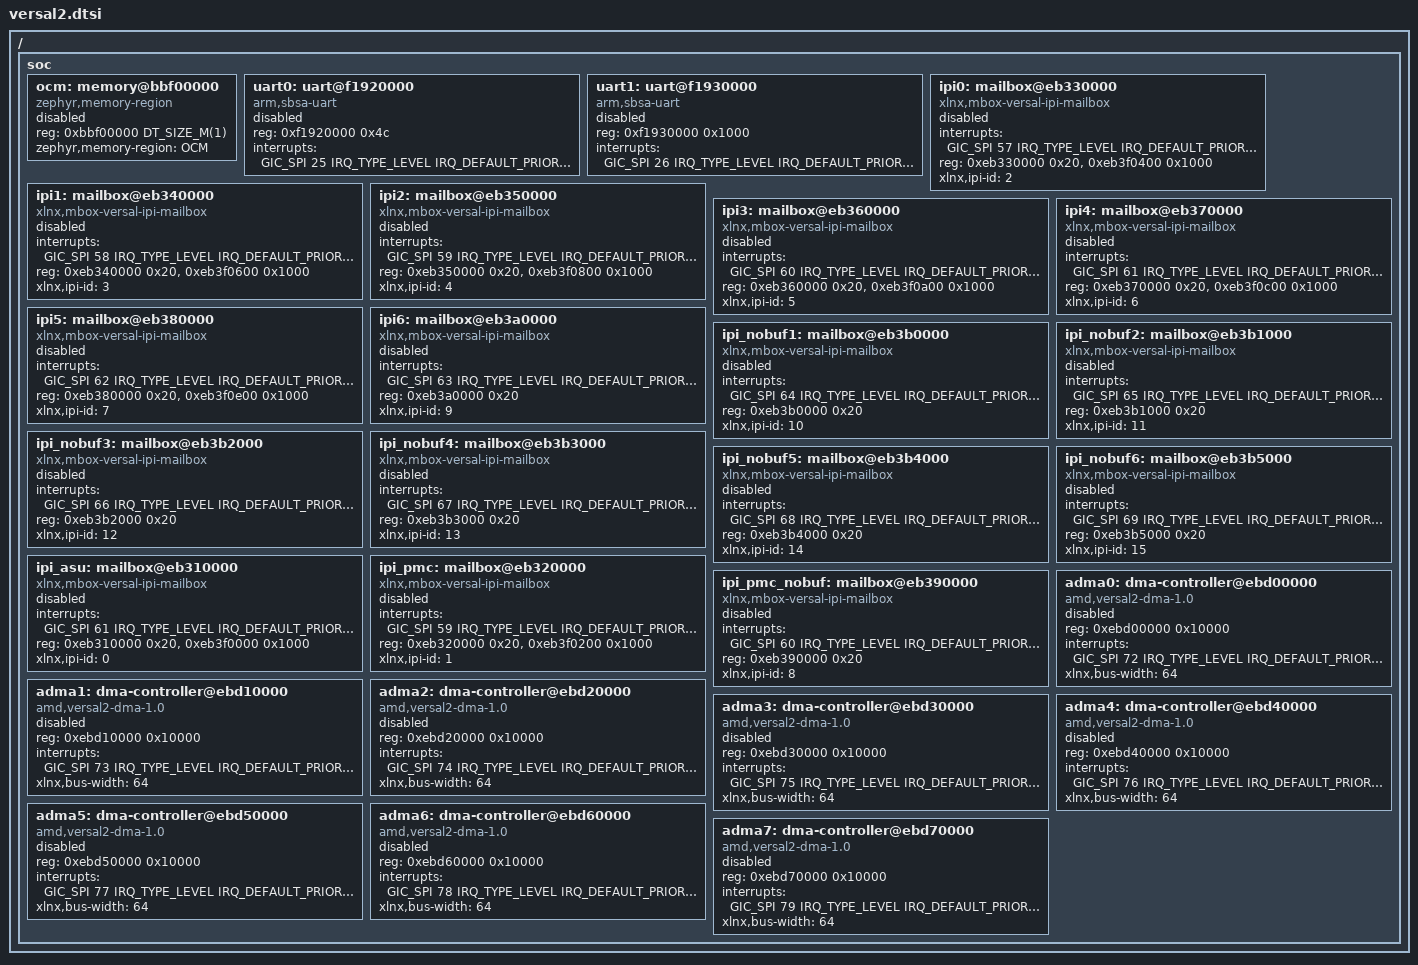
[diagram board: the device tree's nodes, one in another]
/*
 * Copyright (c) 2025, Advanced Micro Devices, Inc.
 *
 * SPDX-License-Identifier: Apache-2.0
 */

/ {
	soc: soc {
		ocm: memory@bbf00000 {
			compatible = "zephyr,memory-region";
			reg = <0xbbf00000 DT_SIZE_M(1)>;
			status = "disabled";
			zephyr,memory-region = "OCM";
		};

		uart0: uart@f1920000 {
			compatible = "arm,sbsa-uart";
			reg = <0xf1920000 0x4c>;
			status = "disabled";
			interrupt-names = "irq_0";
			interrupts = <GIC_SPI 25 IRQ_TYPE_LEVEL IRQ_DEFAULT_PRIORITY>;
		};

		uart1: uart@f1930000 {
			compatible = "arm,sbsa-uart";
			reg = <0xf1930000 0x1000>;
			status = "disabled";
			interrupt-names = "irq_1";
			interrupts = <GIC_SPI 26 IRQ_TYPE_LEVEL IRQ_DEFAULT_PRIORITY>;
		};

		ipi0: mailbox@eb330000 {
			compatible = "xlnx,mbox-versal-ipi-mailbox";
			status = "disabled";
			interrupts = <GIC_SPI 57 IRQ_TYPE_LEVEL IRQ_DEFAULT_PRIORITY>;
			reg = <0xeb330000 0x20>, <0xeb3f0400 0x1000>;
			reg-names = "ctrl", "msg";
			xlnx,ipi-id = <2>;
			#address-cells = <1>;
			#size-cells = <1>;
		};

		ipi1: mailbox@eb340000 {
			compatible = "xlnx,mbox-versal-ipi-mailbox";
			status = "disabled";
			interrupts = <GIC_SPI 58 IRQ_TYPE_LEVEL IRQ_DEFAULT_PRIORITY>;
			reg = <0xeb340000 0x20>, <0xeb3f0600 0x1000>;
			reg-names = "ctrl", "msg";
			xlnx,ipi-id = <3>;
			#address-cells = <1>;
			#size-cells = <1>;
		};

		ipi2: mailbox@eb350000 {
			compatible = "xlnx,mbox-versal-ipi-mailbox";
			status = "disabled";
			interrupts = <GIC_SPI 59 IRQ_TYPE_LEVEL IRQ_DEFAULT_PRIORITY>;
			reg = <0xeb350000 0x20>, <0xeb3f0800 0x1000>;
			reg-names = "ctrl", "msg";
			xlnx,ipi-id = <4>;
			#address-cells = <1>;
			#size-cells = <1>;
		};

		ipi3: mailbox@eb360000 {
			compatible = "xlnx,mbox-versal-ipi-mailbox";
			status = "disabled";
			interrupts = <GIC_SPI 60 IRQ_TYPE_LEVEL IRQ_DEFAULT_PRIORITY>;
			reg = <0xeb360000 0x20>, <0xeb3f0a00 0x1000>;
			reg-names = "ctrl", "msg";
			xlnx,ipi-id = <5>;
			#address-cells = <1>;
			#size-cells = <1>;
		};

		ipi4: mailbox@eb370000 {
			compatible = "xlnx,mbox-versal-ipi-mailbox";
			status = "disabled";
			interrupts = <GIC_SPI 61 IRQ_TYPE_LEVEL IRQ_DEFAULT_PRIORITY>;
			reg = <0xeb370000 0x20>, <0xeb3f0c00 0x1000>;
			reg-names = "ctrl", "msg";
			xlnx,ipi-id = <6>;
			#address-cells = <1>;
			#size-cells = <1>;
		};

		ipi5: mailbox@eb380000 {
			compatible = "xlnx,mbox-versal-ipi-mailbox";
			status = "disabled";
			interrupts = <GIC_SPI 62 IRQ_TYPE_LEVEL IRQ_DEFAULT_PRIORITY>;
			reg = <0xeb380000 0x20>, <0xeb3f0e00 0x1000>;
			reg-names = "ctrl", "msg";
			xlnx,ipi-id = <7>;
			#address-cells = <1>;
			#size-cells = <1>;
		};

		ipi6: mailbox@eb3a0000 {
			compatible = "xlnx,mbox-versal-ipi-mailbox";
			status = "disabled";
			interrupts = <GIC_SPI 63 IRQ_TYPE_LEVEL IRQ_DEFAULT_PRIORITY>;
			reg = <0xeb3a0000 0x20>;
			reg-names = "ctrl";
			xlnx,ipi-id = <9>;
			#address-cells = <1>;
			#size-cells = <1>;
		};

		ipi_nobuf1: mailbox@eb3b0000 {
			compatible = "xlnx,mbox-versal-ipi-mailbox";
			status = "disabled";
			interrupts = <GIC_SPI 64 IRQ_TYPE_LEVEL IRQ_DEFAULT_PRIORITY>;
			reg = <0xeb3b0000 0x20>;
			reg-names = "ctrl";
			xlnx,ipi-id = <10>;
			#address-cells = <1>;
			#size-cells = <1>;
		};

		ipi_nobuf2: mailbox@eb3b1000 {
			compatible = "xlnx,mbox-versal-ipi-mailbox";
			status = "disabled";
			interrupts = <GIC_SPI 65 IRQ_TYPE_LEVEL IRQ_DEFAULT_PRIORITY>;
			reg = <0xeb3b1000 0x20>;
			reg-names = "ctrl";
			xlnx,ipi-id = <11>;
			#address-cells = <1>;
			#size-cells = <1>;
		};

		ipi_nobuf3: mailbox@eb3b2000 {
			compatible = "xlnx,mbox-versal-ipi-mailbox";
			status = "disabled";
			interrupts = <GIC_SPI 66 IRQ_TYPE_LEVEL IRQ_DEFAULT_PRIORITY>;
			reg = <0xeb3b2000 0x20>;
			reg-names = "ctrl";
			xlnx,ipi-id = <12>;
			#address-cells = <1>;
			#size-cells = <1>;
		};

		ipi_nobuf4: mailbox@eb3b3000 {
			compatible = "xlnx,mbox-versal-ipi-mailbox";
			status = "disabled";
			interrupts = <GIC_SPI 67 IRQ_TYPE_LEVEL IRQ_DEFAULT_PRIORITY>;
			reg = <0xeb3b3000 0x20>;
			reg-names = "ctrl";
			xlnx,ipi-id = <13>;
			#address-cells = <1>;
			#size-cells = <1>;
		};

		ipi_nobuf5: mailbox@eb3b4000 {
			compatible = "xlnx,mbox-versal-ipi-mailbox";
			status = "disabled";
			interrupts = <GIC_SPI 68 IRQ_TYPE_LEVEL IRQ_DEFAULT_PRIORITY>;
			reg = <0xeb3b4000 0x20>;
			reg-names = "ctrl";
			xlnx,ipi-id = <14>;
			#address-cells = <1>;
			#size-cells = <1>;
		};

		ipi_nobuf6: mailbox@eb3b5000 {
			compatible = "xlnx,mbox-versal-ipi-mailbox";
			status = "disabled";
			interrupts = <GIC_SPI 69 IRQ_TYPE_LEVEL IRQ_DEFAULT_PRIORITY>;
			reg = <0xeb3b5000 0x20>;
			reg-names = "ctrl";
			xlnx,ipi-id = <15>;
			#address-cells = <1>;
			#size-cells = <1>;
		};

		ipi_asu: mailbox@eb310000 {
			compatible = "xlnx,mbox-versal-ipi-mailbox";
			status = "disabled";
			interrupts = <GIC_SPI 61 IRQ_TYPE_LEVEL IRQ_DEFAULT_PRIORITY>;
			reg = <0xeb310000 0x20>, <0xeb3f0000 0x1000>;
			reg-names = "ctrl", "msg";
			xlnx,ipi-id = <0>;
			#address-cells = <1>;
			#size-cells = <1>;
		};

		ipi_pmc: mailbox@eb320000 {
			compatible = "xlnx,mbox-versal-ipi-mailbox";
			status = "disabled";
			interrupts = <GIC_SPI 59 IRQ_TYPE_LEVEL IRQ_DEFAULT_PRIORITY>;
			reg = <0xeb320000 0x20>, <0xeb3f0200 0x1000>;
			reg-names = "ctrl", "msg";
			xlnx,ipi-id = <1>;
			#address-cells = <1>;
			#size-cells = <1>;
		};

		ipi_pmc_nobuf: mailbox@eb390000 {
			compatible = "xlnx,mbox-versal-ipi-mailbox";
			status = "disabled";
			interrupts = <GIC_SPI 60 IRQ_TYPE_LEVEL IRQ_DEFAULT_PRIORITY>;
			reg = <0xeb390000 0x20>;
			reg-names = "ctrl";
			xlnx,ipi-id = <8>;
			#address-cells = <1>;
			#size-cells = <1>;
		};

		adma0: dma-controller@ebd00000 {
			compatible = "amd,versal2-dma-1.0";
			status = "disabled";
			reg = <0xebd00000 0x10000>;
			#dma-cells = <1>;
			interrupts = <GIC_SPI 72 IRQ_TYPE_LEVEL
				      IRQ_DEFAULT_PRIORITY>;
			clock-names = "clk_main", "clk_apb";
			xlnx,bus-width = <64>;
		};

		adma1: dma-controller@ebd10000 {
			compatible = "amd,versal2-dma-1.0";
			status = "disabled";
			reg = <0xebd10000 0x10000>;
			#dma-cells = <1>;
			interrupts = <GIC_SPI 73 IRQ_TYPE_LEVEL
				      IRQ_DEFAULT_PRIORITY>;
			clock-names = "clk_main", "clk_apb";
			xlnx,bus-width = <64>;
		};

		adma2: dma-controller@ebd20000 {
			compatible = "amd,versal2-dma-1.0";
			status = "disabled";
			reg = <0xebd20000 0x10000>;
			#dma-cells = <1>;
			interrupts = <GIC_SPI 74 IRQ_TYPE_LEVEL
				      IRQ_DEFAULT_PRIORITY>;
			clock-names = "clk_main", "clk_apb";
			xlnx,bus-width = <64>;
		};

		adma3: dma-controller@ebd30000 {
			compatible = "amd,versal2-dma-1.0";
			status = "disabled";
			reg = <0xebd30000 0x10000>;
			#dma-cells = <1>;
			interrupts = <GIC_SPI 75 IRQ_TYPE_LEVEL
				      IRQ_DEFAULT_PRIORITY>;
			clock-names = "clk_main", "clk_apb";
			xlnx,bus-width = <64>;
		};

		adma4: dma-controller@ebd40000 {
			compatible = "amd,versal2-dma-1.0";
			status = "disabled";
			reg = <0xebd40000 0x10000>;
			#dma-cells = <1>;
			interrupts = <GIC_SPI 76 IRQ_TYPE_LEVEL
				      IRQ_DEFAULT_PRIORITY>;
			clock-names = "clk_main", "clk_apb";
			xlnx,bus-width = <64>;
		};

		adma5: dma-controller@ebd50000 {
			compatible = "amd,versal2-dma-1.0";
			status = "disabled";
			reg = <0xebd50000 0x10000>;
			#dma-cells = <1>;
			interrupts = <GIC_SPI 77 IRQ_TYPE_LEVEL
				      IRQ_DEFAULT_PRIORITY>;
			clock-names = "clk_main", "clk_apb";
			xlnx,bus-width = <64>;
		};

		adma6: dma-controller@ebd60000 {
			compatible = "amd,versal2-dma-1.0";
			status = "disabled";
			reg = <0xebd60000 0x10000>;
			#dma-cells = <1>;
			interrupts = <GIC_SPI 78 IRQ_TYPE_LEVEL
				      IRQ_DEFAULT_PRIORITY>;
			clock-names = "clk_main", "clk_apb";
			xlnx,bus-width = <64>;
		};

		adma7: dma-controller@ebd70000 {
			compatible = "amd,versal2-dma-1.0";
			status = "disabled";
			reg = <0xebd70000 0x10000>;
			#dma-cells = <1>;
			interrupts = <GIC_SPI 79 IRQ_TYPE_LEVEL
				      IRQ_DEFAULT_PRIORITY>;
			clock-names = "clk_main", "clk_apb";
			xlnx,bus-width = <64>;
		};
	};
};
